VERSION "Created by Jacob Geigle"

NS_ :

BS_:

BU_:

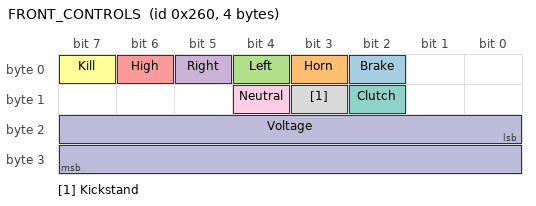
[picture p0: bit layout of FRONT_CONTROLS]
BO_ 608 FRONT_CONTROLS: 4 FC
 SG_ Brake : 2|1@1+ (1,0) [0|1] "" PIND
 SG_ Horn : 3|1@1+ (1,0) [0|1] "" PIND
 SG_ Left : 4|1@1+ (1,0) [0|1] "" PIND
 SG_ Right : 5|1@1+ (1,0) [0|1] "" PIND
 SG_ High : 6|1@1+ (1,0) [0|1] "" PIND
 SG_ Kill : 7|1@1+ (1,0) [0|1] "" PIND
 SG_ Clutch : 10|1@1+ (1,0) [0|1] "" CMDC
 SG_ Kickstand : 11|1@1+ (1,0) [0|1] "" CMDC
 SG_ Neutral : 12|1@1+ (1,0) [0|1] "" CMDC
 SG_ Voltage : 16|16@1+ (0.01,0) [0|200] "" CMDC
